# SAMA7D65D4GN8 register map
Vendor: Microchip Technology; Series: SAMA7D6; File version: 0
Registers are 32-bit, read-write, reset 0x0 unless marked. A register's access mark holds for its fields unless they carry their own. Offsets are from the block's base; [hi:lo] are bit positions; {n}, {i} and the like mark numbered series; 'fields as' and 'values as' point back to an identical list.

## DDRPUBL — DDR SDRAM PHY Utility Block Lite
Base 0xE3804000; register names take the prefix DDR3PHY_
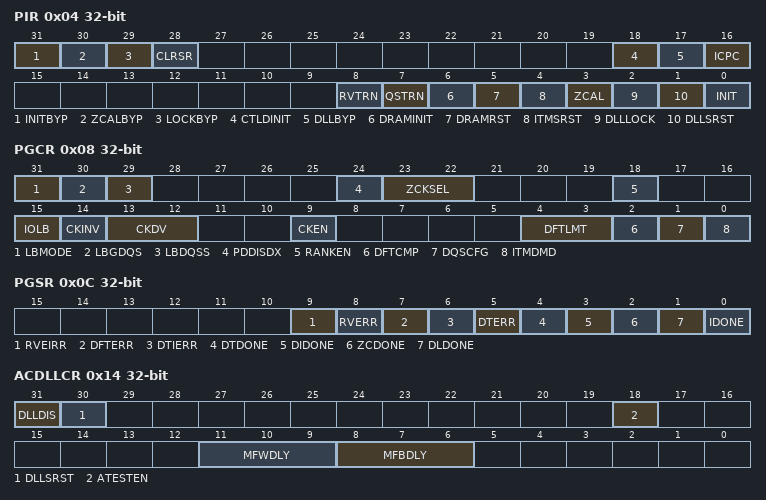
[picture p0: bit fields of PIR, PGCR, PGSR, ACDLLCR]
0x04 PIR — PHY Initialization Register
  [31] INITBYP — Initialization Bypass: Bypasses or stops, if set, all initialization routines currently running, including PHY initialization, DRAM initialization, and PHY training.
  [30] ZCALBYP — Impedance Calibration Bypass: Bypasses or stops, if set, impedance calibration of all ZQ control blocks that automatically triggers after reset. Impedance calibration may be triggered manually using INIT and ZCAL bits of the PIR register. This bit is self-clearing.
  [29] LOCKBYP — DLL Lock Bypass: Bypasses or stops, if set, the waiting of DLLs to lock. DLL lock wait is automatically triggers after reset. DLL lock wait may be triggered manually using INIT and DLLLOCK bits of the PIR register. This bit is self-clearing.
  [28] CLRSR — Clear Status Registers
  [18] CTLDINIT — Controller DRAM Initialization: Indicates if set that DRAM initialization will be performed by the controller. Otherwise if not set it indicates that DRAM initialization will be performed using the built-in initialization sequence or using software through the configuration port.
  [17] DLLBYP — DLL Bypass: A setting of 1 on this bit will put all PHY DLLs in bypass mode. A bypassed DLL is also powered down (disabled).
  [16] ICPC — Initialization Complete Pin Configuration: Specifies how the DFI 2.1 initialization complete output pin should be used to indicate the status of initialization.
  [8] RVTRN — Read DQS gate training (QSTRN) and RV training (RVTRN) should normally be run together. It is expected RVTRN is normally be set whenever PIR.QSTRN is set.
  [7] QSTRN — Read DQS Training: Executes a PUBL training routine to determine the optimum position of the read data DQS strobe for maximum system timing margins.
  [6] DRAMINIT — DRAM Initialization: Executes the DRAM initialization sequence.
  [5] DRAMRST — DRAM Reset (DDR3 Only): Issues a reset to the DRAM (by driving the DRAM reset pin low) and wait 200us. This can be triggered in isolation or with the full DRAM initialization (DRAMINIT). For the latter case, the reset is issued and 200us is waited before starting the full initialization sequence.
  [4] ITMSRST — Interface Timing Module Soft Reset: Soft resets the interface timing modules for the data and data strobes, i.e., it asserts the ITM soft reset (srstb) signal.
  [3] ZCAL — Impedance Calibrate: Performs PHY impedance calibration.
  [2] DLLLOCK — DLL Lock: Waits for the PHY DLLs to lock.
  [1] DLLSRST — DLL Soft Rest: Soft resets all PHY DLLs by driving the DLL soft reset pin.
  [0] INIT — Initialization Trigger: A write of '1' to this bit triggers the DDR system initialization, including PHY initialization, DRAM initialization, and PHY training. The exact initialization steps to be executes are specified in bits 1 to 6 of this register. A bit setting of 1 means the step will be executed as part of the initialization sequence, while a setting of '0' means the step will be bypassed. The initialization trigger bit is self-clearing.
0x08 PGCR — PHY General Configuration Register
  [31] LBMODE — Loopback Mode: Indicates if set that the PHY/PUB is in loopback mode
  [30] LBGDQS — Loopback DQS Gating: Selects the DQS gating mode that should be used when the PHY is in loopback mode, including BIST loopback mode.
  [29] LBDQSS — Loopback DQS Shift: Selects how the read DQS is shifted during loopback to ensure that the read DQS is centered into the read data eye.
  [24] PDDISDX — Power Down Disabled Byte: Indicates if set that the DLL and I/Os of a disabled byte should be powered down.
  [23:22] ZCKSEL — Impedance Clock Divider Select: Impedance Clock Divider Select: Selects the divide ratio for the clock used by the impedance control logic. The source clock for the divider is the configuration port clock signal (cfg_clk or pclk), depending on which configuration port type used (see 'Impedance Calibration' ).
  [18] RANKEN — Rank Enable: Specifies the ranks that are enabled for data-training. Bit 0 controls rank 0, bit 1 controls rank 1, bit 2 controls rank 2, and bit 3 controls rank 3. Setting the bit to '1' enables the rank, and setting it to '0' disables the rank.
  [15] IOLB — I/O Loop-Back Select: Selects where inside the I/O the loop-back of signals happens. Not applicable to D3A I/Os.
  [14] CKINV — CK Invert: Specifies if set that CK/CK# should be inverted. Otherwise CK/CK# toggles with normal polarity.
  [13:12] CKDV — CK Disable Value: Specifies the static value that should be driven on CK/CK# pair(s) when the pair(s) is disabled. CKDV[0] specifies the value for CK and CKDV[1] specifies the value for CK#.
  [9] CKEN — CK Enable: Controls whether the CK going to the SDRAM is enabled (toggling) or disabled (static value defined by CKDV). One bit for each of the three CK pairs.
  [4:3] DFTLMT — DQS Drift Limit: Specifies the expected limit of drift on read data strobes. A drift of this value or greater is reported as a drift error through the host port error flag.
  [2] DFTCMP — DQS Drift Compensation: Enables or disables DQS drift compensation.
  [1] DQSCFG — DQS Gating Configuration: Selects one of the two DQS gating schemes.
  [0] ITMDMD — ITM DDR Mode: Selects whether ITMS uses DQS and DQS# or it only uses DQS.
0x0C PGSR ro — PHY General Status Register
  [9] RVEIRR — Read Valid Training Intermittent Error: If set, indicates that there was an intermittent error during read valid training, such as a pass was followed by a fail then followed by another pass.
  [8] RVERR — Read Valid Training Error: If set, indicates that a valid read valid placement could not be found during read valid training.
  [7] DFTERR — DQS Drift Error: If set, indicates that at least one of the read data strobes has drifted by more than or equal to the drift limit set in the PHY General Configuration Register (PGCR).
  [6] DTIERR — DQS Gate Training Intermittent Error: If set, indicates that there was an intermittent error during DQS gate training, such as a pass was followed by a fail then followed by another pass.
  [5] DTERR — DQS GateTraining Error: If set, indicates that a valid DQS gating window could not be found during DQS gate training.
  [4] DTDONE — Data Training Done: Indicates, if set, that the PHY has finished doing data training.
  [3] DIDONE — DRAM Initialization Done: Indicates if set that DRAM initialization has completed.
  [2] ZCDONE — Impedance Calibration Done: Indicates if set that impedance calibration has completed.
  [1] DLDONE — DLL Lock Done: Indicates if set that DLL locking has completed.
  [0] IDONE — Initialization Done: Indicates if set that the DDR system initialization has completed. This bit is set after all the selected initialization routines in PIR register have completed.
0x10 DLLGCR — DLL General Control Register
  [23] BPS200 — Bypass Mode Frequency Range
0x14 ACDLLCR — AC DLL Control Register
  [31] DLLDIS — DLL Disable: A disabled DLL is bypassed. Default ('0') is DLL enabled.
  [30] DLLSRST — DLL Soft Rest: Soft resets the AC DLL by driving the DLL soft reset pin.
  [18] ATESTEN — Analog Test Enable: Enables the analog test signal to be output on the DLL analog test output (test_out_a). The DLL analog test output is tri-stated when this bit is '0'.
  [11:9] MFWDLY — Master Feed-Forward Delay Trim: Used to trim the delay in the master DLL feedforward path.
  [8:6] MFBDLY — Master Feed-Back Delay Trim: Used to trim the delay in the master DLL feedback path.
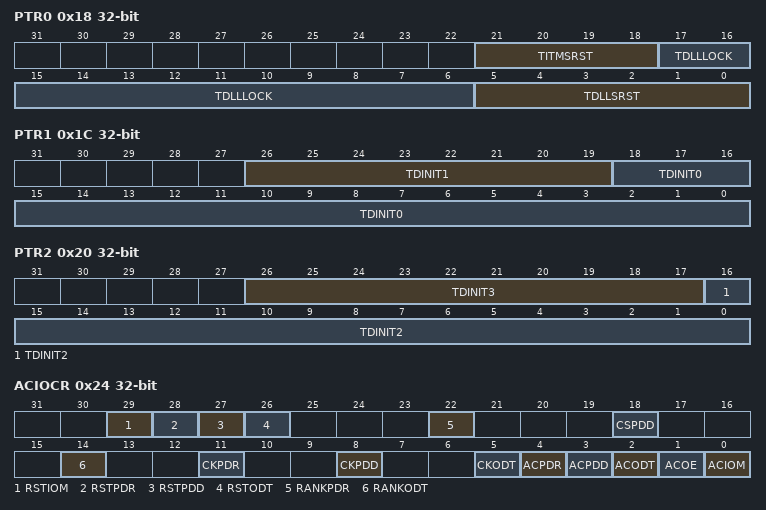
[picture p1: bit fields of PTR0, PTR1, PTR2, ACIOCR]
0x18 PTR0 — PHY Timing Register 0
  [21:18] TITMSRST — ITM Soft Reset Time: Number of configuration clock cycles that the ITM soft reset pin must remain asserted when the soft reset is applied to the ITMs. This must correspond to a value that is equal to or more than 8 controller clock cycles. Default value corresponds to 8 controller clock cycles.
  [17:6] TDLLLOCK — DLL Lock Time: Number of configuration clock cycles for the DLL to stabilize and lock, i.e. number of clock cycles from when the DLL reset pin is de-asserted to when the DLL has locked and is ready for use. Refer to the PHY databook for the DLL lock time. Default value corresponds to 5.12us at 533MHz.
  [5:0] TDLLSRST — DLL Soft Reset Time: Number of configuration clock cycles that the DLL soft reset pin must remain asserted when the soft reset is triggered through the PHY
0x1C PTR1 — PHY Timing Register 1
  [26:19] TDINIT1 — DRAM Initialization Time 1.
  [18:0] TDINIT0 — DRAM Initialization Time 0.
0x20 PTR2 — PHY Timing Register 2
  [26:17] TDINIT3 — DRAM Initialization Time 3.
  [16:0] TDINIT2 — DRAM Initialization Time 2.
0x24 ACIOCR — AC I/O Configuration Register
  [29] RSTIOM — SDRAM Reset I/O Mode: Selects SSTL mode (when set to 0) or CMOS mode (when set to 1) of the I/O for SDRAM Reset.
  [28] RSTPDR — SDRAM Reset Power Down Receiver: Powers down, when set, the input receiver on the I/O for SDRAM RST# pin.
  [27] RSTPDD — SDRAM Reset Power Down Driver: Powers down, when set, the output driver on the I/O for SDRAM RST# pin.
  [26] RSTODT — SDRAM Reset On-Die Termination: Enables, when set, the on-die termination on the I/O for SDRAM RST# pin.
  [22] RANKPDR — Rank Power Down Receiver: Powers down, when set, the input receiver on the I/O
  [18] CSPDD — CS# Power Down Driver: Powers down, when set, the output driver on the I/O for CS#[3:0] pins. PDD[0] controls the power down for CS#[0], PDD[1] controls the power down for CS#[1], and so on. CKE and ODT driver power down is controlled by DSGCR register.
  [14] RANKODT — Rank On-Die Termination: Enables, when set, the on-die termination on the I/O for CKE[3:0], ODT[3:0], and CS#[3:0] pins. RANKODT[0] controls the on-die termination for CKE[0], ODT[0], and CS#[0], RANKODT[1] controls the on-die termination for CKE[1], ODT[1], and CS#[1], and so on.
  [11] CKPDR — CK Power Down Receiver: Powers down, when set, the input receiver on the I/O for CK[0], CK[1], and CK[2] pins, respectively.
  [8] CKPDD — CK Power Down Driver: Powers down, when set, the output driver on the I/O for CK[0], CK[1], and CK[2] pins, respectively.
  [5] CKODT — CK On-Die Termination: Enables, when set, the on-die termination on the I/O for CK[0], CK[1], and CK[2] pins, respectively.
  [4] ACPDR — AC Power Down Receiver: Powers down, when set, the input receiver on the I/O for RAS#, CAS#, WE#, BA[2:0], and A[15:0] pins, as well as the optional DIMM PAR_IN pin and LPDDR TPD pin.
  [3] ACPDD — AC Power Down Driver: Powers down, when set, the output driver on the I/O for RAS#, CAS#, WE#, BA[2:0], and A[15:0] pins, as well as the optional DIMM PAR_IN pin.
  [2] ACODT — Address/Command On-Die Termination: Enables, when set, the on-die termination on the I/O for RAS#, CAS#, WE#, BA[2:0], and A[15:0] pins, as well as the optional DIMM PAR_IN pin and LPDDR TPD pin.
  [1] ACOE — Address/Command Output Enable: Enables, when set, the output driver on the I/O for all address and command pins, as well as the optional DIMM PAR_IN pin and LPDDR TPD pin.
  [0] ACIOM — Address/Command I/O Mode: Selects SSTL mode (when set to 0) or CMOS mode (when set to 1) of the I/O for all address and command pins, as well as the optional DIMM PAR_IN pin and LPDDR TPD pin.
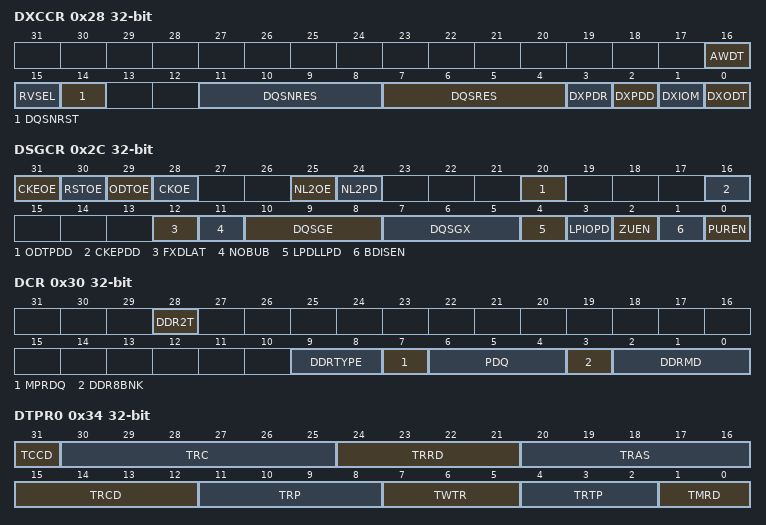
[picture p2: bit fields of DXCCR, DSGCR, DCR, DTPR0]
0x28 DXCCR — DATX8 I/O Configuration Register
  [16] AWDT — Active Window Data Train: Indicates if set that data training (DQS gate training and read valid training) should be performed with active DQS gate window. This is just for debug purposes. The default is to perform training with passive windowing.
  [15] RVSEL — ITMD Read Valid Select: Selects the scheme used for ITMD read valid.
  [14] DQSNRST — DQS# Reset: Indicates, if set, that the ITMS of DQS# should always be put in reset such that its output enable is always '1' and its data output is always '0'. This is done by driving the oe_set_b and do_rst_b pins of this ITMS to '0' in order to force the unused DQS# PAD to a known state of '0' in applications that don't use DQS# such as in LPDDR mode.
  [11:8] DQSNRES — DQS# Resistor: Selects the on-die pull-up/pull-down resistor for DQS# pins. Same encoding as DQSRES.
  [7:4] DQSRES — DQS Resistor: Selects the on-die pull-down/pull-up resistor for DQS pins.
  [3] DXPDR — Data Power Down Receiver: Powers down, when set, the input receiver on I/O for
  [2] DXPDD — Data Power Down Driver: Powers down, when set, the output driver on I/O for DQ, DM, and DQS/DQS# pins of all DATX8 macros. This bit is ORed with the PDD configuration bit of the individual DATX8
  [1] DXIOM — Data I/O Mode: Selects SSTL mode (when set to 0) or CMOS mode (when set to 1) of the I/O for DQ, DM, and DQS/DQS# pins of all DATX8 macros. This bit is ORed with the IOM configuration bit of the individual DATX8
  [0] DXODT — Data On-Die Termination: Enables, when set, the on-die termination on the I/O for DQ, DM, and DQS/DQS# pins of all DATX8 macros. This bit is ORed with the ODT configuration bit of the individual DATX8
0x2C DSGCR — DFI Configuration Register
  [31] CKEOE — SDRAM CKE Output Enable: Enables, when set, the output driver on the I/O for SDRAM CKE pins.
  [30] RSTOE — SDRAM Reset Output Enable: Enables, when set, the output driver on the I/O for SDRAM RST# pin.
  [29] ODTOE — SDRAM ODT Output Enable: Enables, when set, the output driver on the I/O for SDRAM ODT pins.
  [28] CKOE — SDRAM CK Output Enable: Enables, when set, the output driver on the I/O for SDRAM CK/CK# pins.
  [25] NL2OE — Non-LPDDR2/LPDDR3 Output Enable: Enables, when set, the output driver on the I/O for non-LPDDR2/LPDDR3 (ODT, RAS#, CAS#, WE#, and BA) pins. This may be used when a chip that is designed for both LPDDR2/LPDDR3 and other DDR modes is being used in LPDDR2/LPDDR3 mode. For these pins, the I/O output enable signal (OE) is an AND of this bit and the respective output enable bit in ACIOCR or DSGCR registers.
  [24] NL2PD — Non-LPDDR2/LPDDR3 Power Down: Powers down, when set, the output driver and the input receiver on the I/O for non-LPDDR2/LPDDR3 (ODT, RAS#, CAS#, WE#,
  [20] ODTPDD — ODT Power Down Driver: Powers down, when set, the output driver on the I/O for ODT[3:0] pins. ODTPDD[0] controls the power down for ODT[0], ODTPDD[1] controls the power down for ODT[1], and so on.
  [16] CKEPDD — CKE Power Down Driver: Powers down, when set, the output driver on the I/O for CKE[3:0] pins. CKEPDD[0] controls the power down for CKE[0], CKEPDD[1] controls the power down for CKE[1], and so on.
  [12] FXDLAT — Fixed Latency: Specified whether all reads should be returned to the controller with a fixed read latency. Enabling fixed read latency increases the read latency.
  [11] NOBUB — No Bubbles: Specified whether reads should be returned to the controller with no bubbles. Enabling no-bubble reads increases the read latency.
  [10:8] DQSGE — DQS Gate Early: Specifies the number of clock cycles for which the DQS gating must be enabled earlier than its normal position. Only applicable when using PDQSR I/O cell, passive DQS gating and no drift compensation. This field is recommended to be set to zero for all DDR types other than
  [7:5] DQSGX — DQS Gate Extension: Specifies the number of clock cycles for which the DQS gating must be extended beyond the normal burst length width. Only applicable when using PDQSR I/O cell, passive DQS gating and no drift compensation. This field is recommended to be set to zero for all DDR types other than
  [4] LPDLLPD — Low Power DLL Power Down: Specifies if set that the PHY should respond to the DFI low power opportunity request and power down the DLL of the PHY if the wakeup time request satisfies the DLL lock time.
  [3] LPIOPD — Low Power I/O Power Down: Specifies if set that the PHY should respond to the DFI low power opportunity request and power down the I/Os of the PHY.
  [2] ZUEN — Impedance Update Enable: Specifies if set that the PHY should perform impedance calibration (update) whenever there is a controller initiated DFI update request.
  [1] BDISEN — Byte Disable Enable: Specifies if set that the PHY should respond to DFI byte disable request. Otherwise the byte disable from the DFI is ignored in which case bytes can only be disabled using the DXnGCR register.
  [0] PUREN — PHY Update Request Enable: Specifies if set, that the PHY should issue PHYinitiated DFI update request when there is DQS drift of more than 3/4 of a clock cycle within one continuous (back-to-back) read burst. By default the PHY issues PHYinitiated update requests and the controller should respond otherwise the PHY may return erroneous values. The option to disable it is provided only for silicon evaluation and testing.
0x30 DCR — DRAM Configuration Register
  [28] DDR2T — DDR 2T Timing: Indicates if set that 2T timing should be used by PUB internally generated SDRAM transactions.
  [9:8] DDRTYPE — DDR Type: Selects the DDR type for the specified LPDDR mode.
  [7] MPRDQ — Multi-Purpose Register (MPR) DQ (DDR3 Only): Specifies the value that is driven on non-primary DQ pins during MPR reads.
  [6:4] PDQ — Primary DQ (DDR3 Only): Specifies the DQ pin in a byte that is designated as a primary pin for Multi-Purpose Register (MPR) reads. Valid values are 0 to 7 for DQ[0] to DQ[7], respectively.
  [3] DDR8BNK — DDR 8-Bank: Indicates if set that the SDRAM used has 8 banks. tRPA = tRP+1 and tFAW are used for 8-bank DRAMs, other tRPA = tRP and no tFAW is used. Note that
  [2:0] DDRMD — DDR Mode: SDRAM DDR mode.
0x34 DTPR0 — SDRAM Timing Parameters Register 0
  [31] TCCD — Read to read and write to write command delay.
  [30:25] TRC — Activate to activate command delay (same bank). Valid values are 2 to 42.
  [24:21] TRRD — Activate to activate command delay (different banks). Valid values are 1 to 8.
  [20:16] TRAS — Activate to precharge command delay. Valid values are 2 to 31.
  [15:12] TRCD — Activate to read or write delay. Minimum time from when an activate command is issued to when a read or write to the activated row can be issued. Valid values are 2 to 11.
  [11:8] TRP — Precharge command period: The minimum time between a precharge command and any other command. Note that the Controller automatically derives tRPA for 8bank DDR2 devices by adding 1 to tRP. Valid values are 2 to 11.
  [7:5] TWTR — Internal write to read command delay. Valid values are 1 to 6.
  [4:2] TRTP — Internal read to precharge command delay. Valid values are 2 to 6. Note that even though RTP does not apply to JEDEC DDR devices, this parameter must still be set to a minimum value of 2 for DDR because the Controller always uses the DDR2 equation, AL + BL/2 + max(RTP,2) - 2, to compute the read to precharge timing (which is BL/2 for JEDEC DDR).
  [1:0] TMRD — Load mode cycle time: The minimum time between a load mode register command and any other command. For DDR3 this is the minimum time between two load mode register commands. Valid values for DDR2 are 2 to 3. For DDR3, the value used for tMRD is 4 plus the value programmed in these bits, i.e. tMRD value for DDR3 ranges from 4 to 7. For LPDDR3, the value used for tMRD is 8 plus the value programmed in these bits.
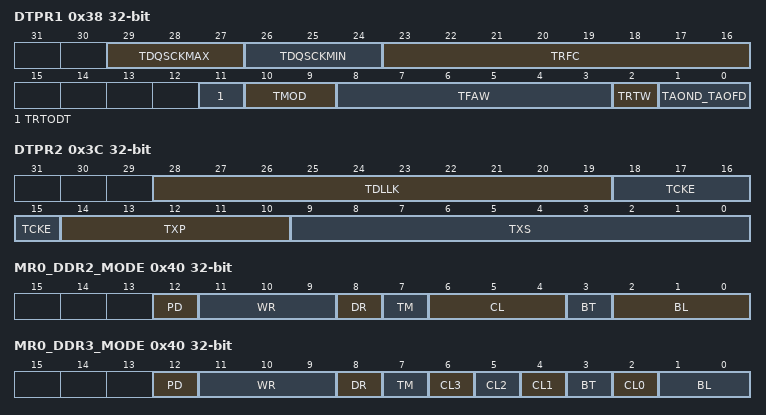
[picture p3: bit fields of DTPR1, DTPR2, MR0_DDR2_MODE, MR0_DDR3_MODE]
0x38 DTPR1 — SDRAM Timing Parameters Register 1
  [29:27] TDQSCKMAX — Maximum DQS output access time from CK/CK# (LPDDR2 only). This value is used for implementing read-to-write spacing. Valid values are 1 to 7.
  [26:24] TDQSCKMIN — DQS output access time from CK/CK# (LPDDR2/3 only). This value is used for computing the read latency. Valid values are 0 to 7. This value is derived from the corresponding parameter in the SDRAM datasheet divided by the clock cycle time without rounding up. The fractional remainder is automatically adjusted for by data training in quarter clock cycle units. If data training is not performed then this fractional remainder must be converted to quarter clock cycle units and the gating registers (DXnDQSTR) adjusted accordingly.
  [23:16] TRFC — Refresh-to-Refresh: Indicates the minimum time, in clock cycles, between two refresh commands or between a refresh and an active command. This is derived from the minimum refresh interval from the datasheet, tRFC(min), divided by the clock cycle time. The default number of clock cycles is for the largest JEDEC tRFC(min parameter value supported.
  [11] TRTODT — Read to ODT delay (DDR3 only). Specifies whether ODT can be enabled immediately after the read post-amble or one clock delay has to be added.
  [10:9] TMOD — Load mode update delay (DDR3 only). The minimum time between a load mode register command and a non-load mode register command.
  [8:3] TFAW — 4-bank activate period. No more than 4-bank activate commands may be issued in a given tFAW period. Only applies to 8-bank devices. Valid values are 2 to 31.
  [2] TRTW — Read to Write command delay.
  [1:0] TAOND_TAOFD — ODT Turn-On/Turn-Off Delays (DDR2 only)
0x3C DTPR2 — SDRAM Timing Parameters Register 2
  [28:19] TDLLK — DLL locking time. Valid values are 2 to 1023.
  [18:15] TCKE — CKE minimum pulse width. Also specifies the minimum time that the SDRAM must remain in power down or self refresh mode. For DDR3 this parameter must be set to the value of tCKESR which is usually bigger than the value of tCKE. Valid values are 2 to 15.
  [14:10] TXP — Power down exit delay. The minimum time between a power down exit command and any other command. This parameter must be set to the maximum of the various minimum power down exit delay parameters specified in the SDRAM datasheet, i.e. max(tXP, tXARD, tXARDS) for DDR2 and max(tXP, tXPDLL) for DDR3. Valid values are 2 to 31.
  [9:0] TXS — Self refresh exit delay. The minimum time between a self refresh exit command and any other command. This parameter must be set to the maximum of the various minimum self refresh exit delay parameters specified in the SDRAM datasheet, i.e. max(tXSNR, tXSRD) for DDR2 and max(tXS, tXSDLL) for DDR3. Valid values are 2 to 1023.
0x40 MR0_DDR2_MODE — Mode Register
  [12] PD — Power-Down Control
  [11:9] WR — Write Recovery
  [8] DR — DLL Reset
  [7] TM — Operating Mode
  [6:4] CL — CAS Latency
  [3] BT — Burst Type
  [2:0] BL — Burst Length
0x40 MR0_DDR3_MODE (alternate view of MR0_DDR2_MODE) — Mode Register
  [12] PD — Power-Down Control
  [11:9] WR — Write Recovery
  [8] DR — DLL Reset
  [7] TM — Operating Mode
  [6] CL3 — CAS Latency
  [5] CL2 — CAS Latency
  [4] CL1 — CAS Latency
  [3] BT — Burst Type
  [2] CL0 — CAS Latency
  [1:0] BL — Burst Length
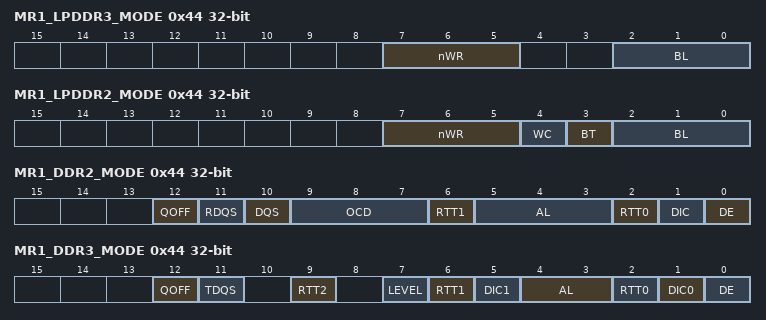
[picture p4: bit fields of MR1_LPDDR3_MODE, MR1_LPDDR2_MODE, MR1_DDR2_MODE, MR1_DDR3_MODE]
0x44 MR1_LPDDR3_MODE — Extended Mode Register 1
  [7:5] nWR — Write Recovery
  [2:0] BL — Burst Length
0x44 MR1_LPDDR2_MODE (alternate view of MR1_LPDDR3_MODE) — Extended Mode Register 1
  [7:5] nWR — Write Recovery
  [4] WC — Wrap Control
  [3] BT — Burst Type
  [2:0] BL — Burst Length
0x44 MR1_DDR2_MODE (alternate view of MR1_LPDDR3_MODE) — Extended Mode Register 1
  [12] QOFF — Output Enable/Disable
  [11] RDQS — RDQS Enable/Disable
  [10] DQS — DDR_DQSN Enable/Disable
  [9:7] OCD — Off-Chip Driver (OCD) Impedance Calibration
  [6] RTT1 — On-Die Termination
  [5:3] AL — Posted CAS Additive Latency
  [2] RTT0 — On-Die Termination
  [1] DIC — Output Driver Impedance Control
  [0] DE — DLL Enable/Disable
0x44 MR1_DDR3_MODE (alternate view of MR1_LPDDR3_MODE) — Extended Mode Register 1
  [12] QOFF — Output Enable/Disable
  [11] TDQS — Termination Data Strobe
  [9] RTT2 — On-Die Termination
  [7] LEVEL — Write Leveling Enable
  [6] RTT1 — On-Die Termination
  [5] DIC1 — Output Driver Impedance Control
  [4:3] AL — Posted CAS Additive Latency
  [2] RTT0 — On-Die Termination
  [1] DIC0 — Output Driver Impedance Control
  [0] DE — DLL Enable/Disable
0x48 MR2_LPDDR3_MODE — Extended Mode Register 2
  [3:0] RL_WL — Read and Write Latency
0x48 MR2_LPDDR2_MODE (alternate view of MR2_LPDDR3_MODE) — Extended Mode Register 2
  [3:0] RL_WL — Read and Write Latency
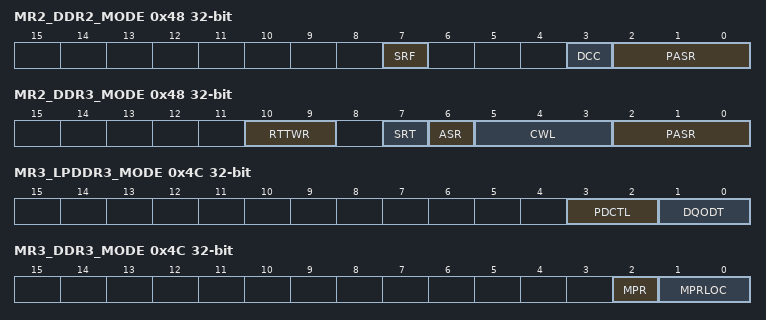
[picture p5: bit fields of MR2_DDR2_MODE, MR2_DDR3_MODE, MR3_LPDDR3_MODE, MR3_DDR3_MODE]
0x48 MR2_DDR2_MODE (alternate view of MR2_LPDDR3_MODE) — Extended Mode Register 2
  [7] SRF — Self-Refresh Rate
  [3] DCC — Duty Cycle Corrector
  [2:0] PASR — Partial Array Self Refresh
0x48 MR2_DDR3_MODE (alternate view of MR2_LPDDR3_MODE) — Extended Mode Register 2
  [10:9] RTTWR — Dynamic ODT
  [7] SRT — Self-Refresh Temperature Range
  [6] ASR — Auto Self-Refresh
  [5:3] CWL — CAS Write Latency
  [2:0] PASR — Partial Array Self Refresh
0x4C MR3_LPDDR3_MODE — Extended Mode Register 3
  [3:2] PDCTL — Power-Down Control
  [1:0] DQODT — On-Die Termination
0x4C MR3_LPDDR2_MODE (alternate view of MR3_LPDDR3_MODE) — Extended Mode Register 3
  [3:0] DS — Drive Strength
0x4C MR3_DDR2_MODE (alternate view of MR3_LPDDR3_MODE) — Extended Mode Register 3
0x4C MR3_DDR3_MODE (alternate view of MR3_LPDDR3_MODE) — Extended Mode Register 3
  [2] MPR — Multi-Purpose Register Enable
  [1:0] MPRLOC — Multi-Purpose Register (MPR) Location
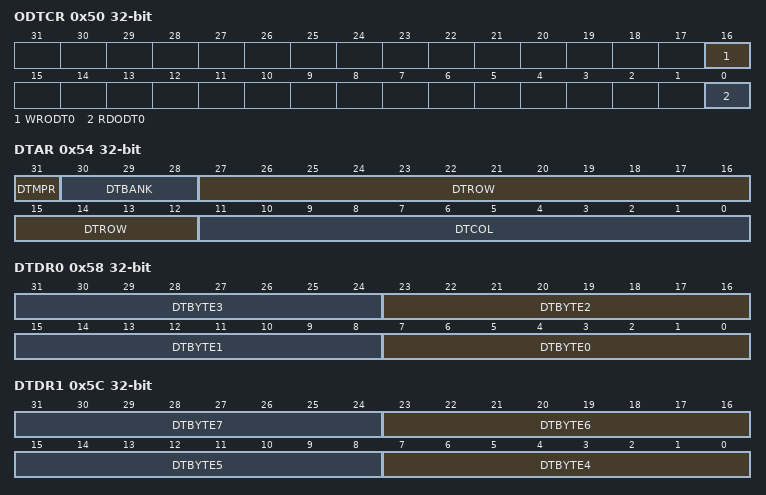
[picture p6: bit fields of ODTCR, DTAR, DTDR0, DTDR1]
0x50 ODTCR — ODT Configuration Register
  [16] WRODT0 — Write ODT: Specifies whether ODT should be enabled ('1') or disabled ('0') on each of the up to four ranks when a write command is sent to rank n. WRODT0,
  [0] RDODT0
0x54 DTAR — Data Training Address Register
  [31] DTMPR — Data Training Using MPR (DDR3 Only): Specifies, if set, that data-training should use the SDRAM Multi-Purpose Register (MPR) register. Otherwise data-training is performed by first writing to some locations in the SDRAM and then reading them back.
  [30:28] DTBANK — Data Training Bank Address: Selects the SDRAM bank address to be used during data training.
  [27:12] DTROW — Data Training Row Address: Selects the SDRAM row address to be used during data training.
  [11:0] DTCOL — Data Training Column Address: Selects the SDRAM column address to be used during data training. The lower four bits of this address must always be '0000'.
0x58 DTDR0 — Data Training Data Register 0
  [8n+7:8n] DTBYTE{n} (n=0..3) — Data Training Data: The first 4 bytes of data used during data training. This same data byte is used for each Byte Lane. Default sequence is a walking 1 while toggling data every data cycle.
0x5C DTDR1 — Data Training Data Register 1
  [8n-25:8n-32] DTBYTE{n} (n=4..7) — Data Training Data: The second 4 bytes of data used during data training. This same data byte is used for each Byte Lane. Default sequence is a walking 1 while toggling data every data cycle.
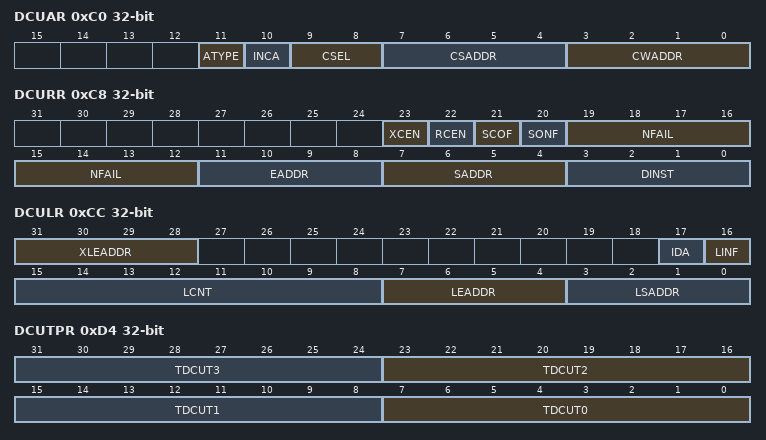
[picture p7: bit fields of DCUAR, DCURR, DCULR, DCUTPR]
0xC0 DCUAR — DCU Address Register
  [11] ATYPE — Access Type: Specifies the type of access to be performed using this address. Valid values are: 0 = Write access
  [10] INCA — Increment Address: Specifies, if set, that the cache address specified in WADDR and SADDR should be automatically incremented after each access of the cache. The increment happens in such a way that all the slices of a selected word are first accessed before going to the next word.
  [9:8] CSEL — Cache Select: Selects the cache to be accessed.
  [7:4] CSADDR — Cache Slice Address: Address of the cache slice to be accessed.
  [3:0] CWADDR — Cache Word Address: Address of the cache word to be accessed.
0xC4 DCUDR — DCU Data Register
  [31:0] CDATA — Cache Data: Data to be written to or read from a cache. This data corresponds to the cache word slice specified by the DCU Address Register.
0xC8 DCURR — DCU Run Register
  [23] XCEN — Expected Compare Enable: Indicates if set that read data coming back from the SDRAM should be should be compared with the expected data.
  [22] RCEN — Read Capture Enable: Indicates if set that read data coming back from the SDRAM should be captured into the read data cache.
  [21] SCOF — Stop Capture On Full: Specifies if set that the capture of read data should stop when the capture cache is full.
  [20] SONF — Stop On Nth Fail: Specifies if set that the execution of commands and the capture of read data should stop when there are N read data failures. The number of failures is specified by NFAIL. Otherwise commands execute until the end of the program or until manually stopped using a STOP command.
  [19:12] NFAIL — Number of Failures: Specifies the number of failures after which the execution of commands and the capture of read data should stop if SONF bit of this register is set. Execution of commands and the capture of read data will stop after (NFAIL+1) failures if SONF is set.
  [11:8] EADDR — End Address: Cache word address where the execution of command should end.
  [7:4] SADDR — Start Address: Cache word address where the execution of commands should begin.
  [3:0] DINST — DCU Instruction: Selects the DCU command to be executed.
0xCC DCULR — DCU Loop Register
  [31:28] XLEADDR — Expected Data Loop End Address: The last expected data cache word address that contains valid expected data. Expected data should looped between 0 and this address.
  [17] IDA — Increment DRAM Address: Indicates if set that DRAM addresses should be incremented every time a DRAM read/write command inside the loop is executed.
  [16] LINF — Loop Infinite: Indicates if set that the loop should be executed indefinitely until stopped by the STOP command. Otherwise the loop is execute LCNT times.
  [15:8] LCNT — Loop Count: The number of times that the loop should be executed if LINF is not set.
  [7:4] LEADDR — Loop End Address: Command cache word address where the loop should end.
  [3:0] LSADDR — Loop Start Address: Command cache word address where the loop should start.
0xD0 DCUGCR — DCU General Configuration Register
  [15:0] RCSW — Read Capture Start Word: The capture and compare of read data should start after Nth word. For example setting this value to 12 will skip the first 12 read data.
0xD4 DCUTPR — DCU Timing Parameter Register
  [8n+7:8n] TDCUT{n} (n=0..3) — DCU Generic Timing Parameter {n}.
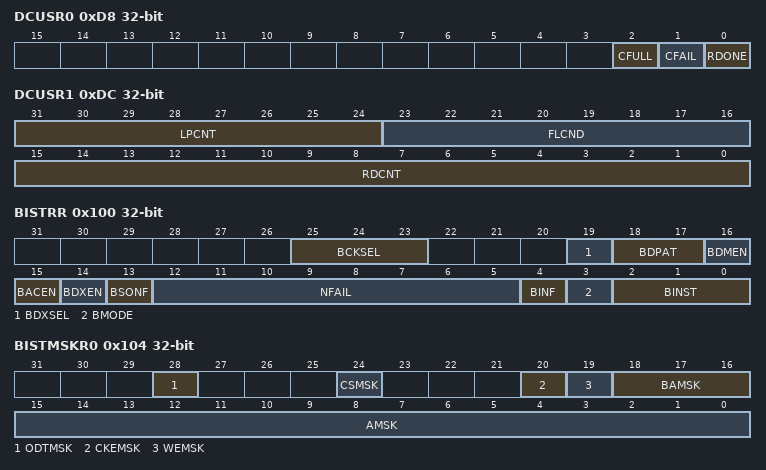
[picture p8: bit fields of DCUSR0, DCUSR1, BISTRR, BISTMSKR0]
0xD8 DCUSR0 — DCU Status-0 Register
  [2] CFULL — Capture Full: Indicates if set that the capture cache is full.
  [1] CFAIL — Capture Fail: Indicates if set that at least one read data word has failed.
  [0] RDONE — Run Done: Indicates if set that the DCU has finished executing the commands in the command cache. This bit is also set to indicate that a STOP command has successfully been executed and command execution has stopped.
0xDC DCUSR1 — DCU Status-1 Register
  [31:24] LPCNT — Loop Count: Indicates the value of the loop count. This is useful when the program has stooped because of failures to assess how many reads were executed before first fail.
  [23:16] FLCND — Fail Count: Number of read words that have failed.
  [15:0] RDCNT — Read Count: Number of read words returned from the SDRAM.
0x100 BISTRR — BIST Run Register
  [25:23] BCKSEL — BIST DDR_CLK Select
  [19] BDXSEL — BIST Data Byte Lane Select
  [18:17] BDPAT — BIST Data Pattern
  [16] BDMEN — BIST Data Mask Enable
  [15] BACEN — BIST AC Enable
  [14] BDXEN — BIST Data Enable
  [13] BSONF — BIST Stop On Nth Fail
  [12:5] NFAIL — Number of Failures
  [4] BINF — BIST Infinite Run
  [3] BMODE — BIST Mode
  [2:0] BINST — BIST Instruction
0x104 BISTMSKR0 — BIST Mask 0 Register
  [28] ODTMSK — ODT Mask Bit
  [24] CSMSK — DDR_CSN Mask Bit
  [20] CKEMSK — DDR_CKE Mask Bit
  [19] WEMSK — DDR_WEN Mask Bit
  [18:16] BAMSK — DDR_BA Mask Bit
  [15:0] AMSK — DDR_A Mask Bit
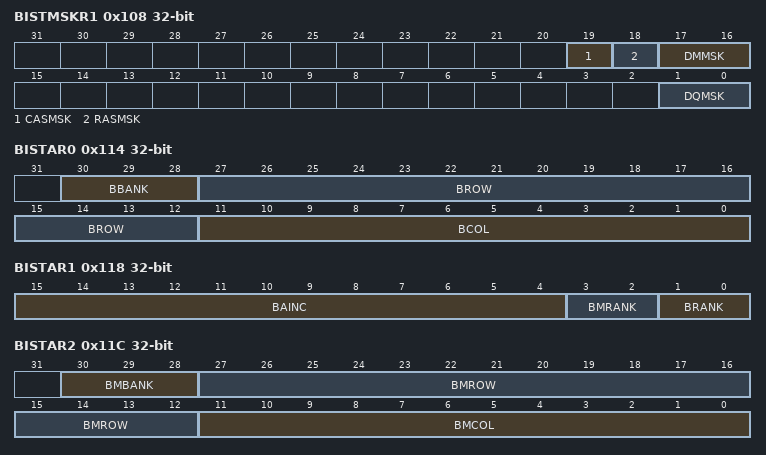
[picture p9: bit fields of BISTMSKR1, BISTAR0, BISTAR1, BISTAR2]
0x108 BISTMSKR1 — BIST Mask 1 Register
  [19] CASMSK — DDR_CASN Mask Bit
  [18] RASMSK — DDR_RASN Mask Bit
  [17:16] DMMSK — DDR_DQM Mask Bit
  [1:0] DQMSK — DDR_D Mask Bit
0x10C BISTWCR — BIST Word Count Register
  [15:0] BWCNT — BIST Word Count
0x110 BISTLSR — BIST LFSR Seed Register
  [31:0] SEED — LFSR seed for pseudo-random BIST patterns.
0x114 BISTAR0 — BIST Address 0 Register
  [30:28] BBANK — BIST Bank Address
  [27:12] BROW — BIST Row Address
  [11:0] BCOL — BIST Column Address
0x118 BISTAR1 — BIST Address 1 Register
  [15:4] BAINC — BIST Address Increment
  [3:2] BMRANK — BIST Maximum Rank
  [1:0] BRANK — BIST Rank
0x11C BISTAR2 — BIST Address 2 Register
  [30:28] BMBANK — BIST Maximum Bank Address
  [27:12] BMROW — BIST Maximum Row Address
  [11:0] BMCOL — BIST Maximum Column Address
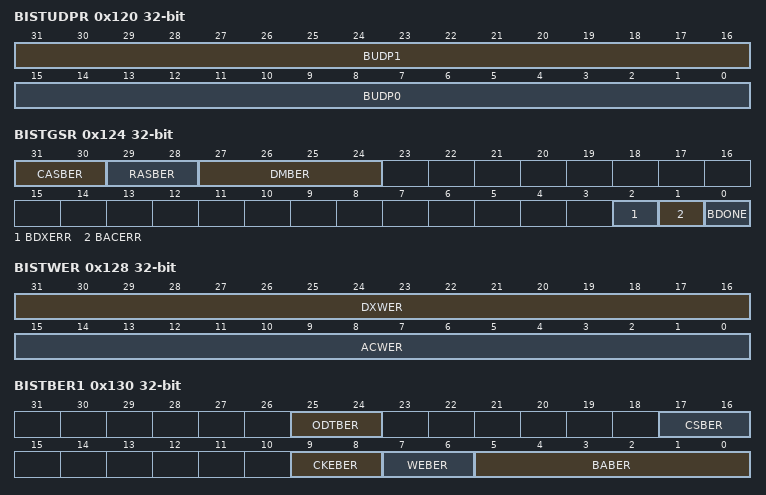
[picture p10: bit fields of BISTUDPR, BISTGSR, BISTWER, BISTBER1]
0x120 BISTUDPR — BIST User Data Pattern Register
  [31:16] BUDP1 — BIST User Data Pattern 1
  [15:0] BUDP0 — BIST User Data Pattern 0
0x124 BISTGSR — BIST General Status Register
  [31:30] CASBER — DDR_CASN Bit Error
  [29:28] RASBER — DDR_RASN Bit Error
  [27:24] DMBER — DDR_DQM Bit Error
  [2] BDXERR — BIST Data Error
  [1] BACERR — BIST Address/Command Error
  [0] BDONE — BIST Done
0x128 BISTWER — BIST Word Error Register
  [31:16] DXWER — Byte Word Error
  [15:0] ACWER — Address/Command Word Error
0x12C BISTBER0 — BIST Bit Error 0 Register
  [31:0] ABER — Address Bit Error
0x130 BISTBER1 — BIST Bit Error 1 Register
  [25:24] ODTBER — DDR_ODT Bit Error
  [17:16] CSBER — DDR_CSN Bit Error
  [9:8] CKEBER — DDR_CKE Bit Error
  [7:6] WEBER — DDR_WEN Bit Error
  [5:0] BABER — Bank Address Bit Error
0x134 BISTBER2 — BIST Bit Error 2 Register
  [31:0] DQBER — Data Bit Error
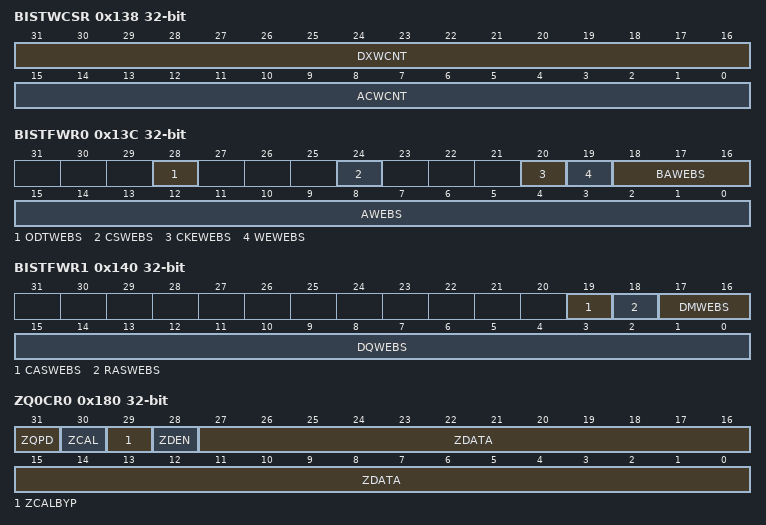
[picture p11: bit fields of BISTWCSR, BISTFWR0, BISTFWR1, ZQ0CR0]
0x138 BISTWCSR — BIST Word Count Status Register
  [31:16] DXWCNT — Byte Word Count
  [15:0] ACWCNT — Address/Command Word Count
0x13C BISTFWR0 — BIST Fail Word 0 Register
  [28] ODTWEBS — DDR_ODT Word Error Bit Status
  [24] CSWEBS — DDR_CSN Word Error Bit Status
  [20] CKEWEBS — DDR_CKE Word Error Bit Status
  [19] WEWEBS — DDR_WEN Word Error Bit Status
  [18:16] BAWEBS — DDR_BA Word Error Bit Status
  [15:0] AWEBS — DDR_A Word Error Bit Status
0x140 BISTFWR1 — BIST Fail Word 1 Register
  [19] CASWEBS — DDR_CASN Word Error Bit Status
  [18] RASWEBS — DDR_RASN Word Error Bit Status
  [17:16] DMWEBS — DDR_DQM Word Error Bit Status
  [15:0] DQWEBS — DDR_D Word Error Bit Status
0x180 ZQ0CR0 — ZQ Impedence Control Register 0
  [31] ZQPD — ZQ Power Down
  [30] ZCAL — Impedance Calibration Trigger
  [29] ZCALBYP — Impedance Calibration Bypass
  [28] ZDEN — Impedance Override Enable
  [27:0] ZDATA — Impedance Override Data
0x184 ZQ0CR1 — ZQ Impedence Control Register 1
  [7:0] ZPROG — Impedance Divide Ratio
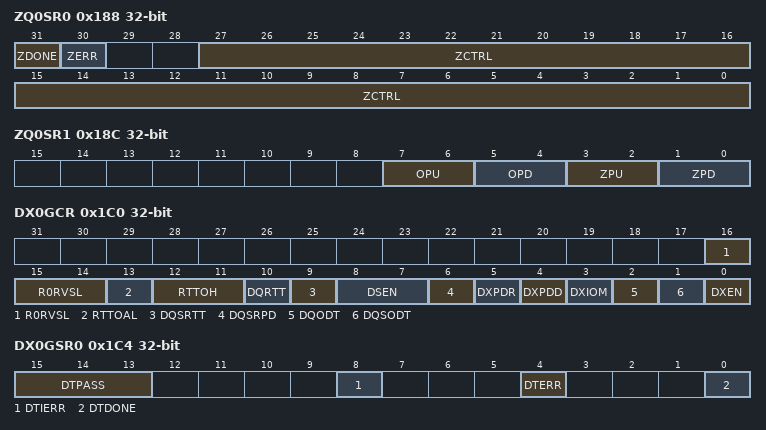
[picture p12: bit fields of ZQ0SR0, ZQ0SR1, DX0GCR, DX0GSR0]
0x188 ZQ0SR0 — ZQ Impedence Control Status Register 0
  [31] ZDONE — Impedance Calibration Done
  [30] ZERR — Impedance Calibration Error
  [27:0] ZCTRL — Impedance Control
0x18C ZQ0SR1 — ZQ Impedence Control Status Register 1
  [7:6] OPU — On-Die Termination (ODT) Pull-Up Calibration Status
  [5:4] OPD — On-Die Termination (ODT) Pull-Down Calibration Status
  [3:2] ZPU — Output Impedance Pull-Up Calibration Status
  [1:0] ZPD — Output Impedance Pull-Down Calibration Status
0x1C0 DX0GCR — DATX8 General Configuration Register
  [16:14] R0RVSL — Rank 0 ITMD Read Valid System Latency
  [13] RTTOAL — RTT On Additive Latency
  [12:11] RTTOH — RTT Output Hold
  [10] DQRTT — DDR_D Dynamic RTT Control
  [9] DQSRTT — DDR_DQS Dynamic RTT Control
  [8:7] DSEN — Write DDR_DQS Enable
  [6] DQSRPD — DQSR Power Down
  [5] DXPDR — Data Power Down Receiver
  [4] DXPDD — Data Power Down Driver
  [3] DXIOM — Data I/O Mode
  [2] DQODT — Data On-Die Termination
  [1] DQSODT — DDR_DQS On-Die Termination
  [0] DXEN — Data Byte Enable
0x1C4 DX0GSR0 — DATX8 General Status Register 0
  [15:13] DTPASS — DDR_DQS GateTraining Pass Count
  [8] DTIERR — DDR_DQS Gate Training Intermittent Error
  [4] DTERR — DDR_DQS Gate Training Error
  [0] DTDONE — Data Training Done
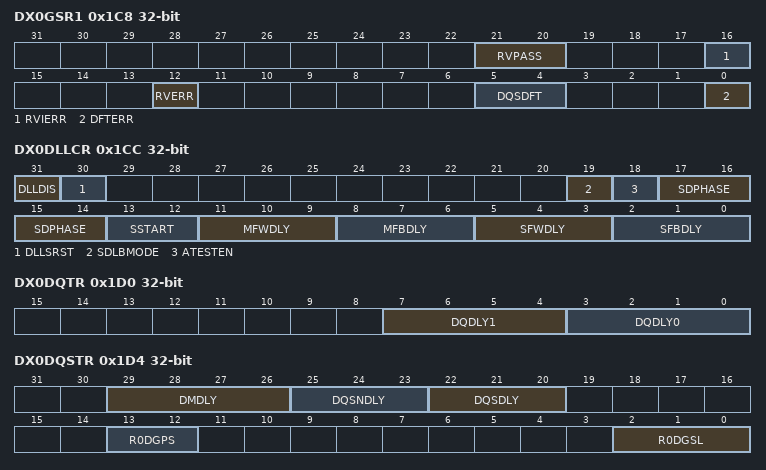
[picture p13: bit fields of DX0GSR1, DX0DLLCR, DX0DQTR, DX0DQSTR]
0x1C8 DX0GSR1 — DATX8 General Status Register 1
  [21:20] RVPASS — Read Valid Training Pass Count
  [16] RVIERR — Read Valid Training Intermittent Error
  [12] RVERR — Read Valid Training Error
  [5:4] DQSDFT — DQS Drift
  [0] DFTERR — DQS Drift Error
0x1CC DX0DLLCR — DATX8 DLL Control Register
  [31] DLLDIS — DLL Disable
  [30] DLLSRST — DLL Soft Reset
  [19] SDLBMODE — Client DLL Loopback Mode
  [18] ATESTEN — Analog Test Enable
  [17:14] SDPHASE — Client DLL Phase Trim
  [13:12] SSTART — Client Auto Start-Up
  [11:9] MFWDLY — Host Feed-Forward Delay Trim
  [8:6] MFBDLY — Host Feedback Delay Trim
  [5:3] SFWDLY — Client Feed-Forward Delay Trim
  [2:0] SFBDLY — Client Feedback Delay Trim
0x1D0 DX0DQTR — DATX8 DQ Timing Register
  [7:4] DQDLY1 — DDR_D Delay
  [3:0] DQDLY0 — DDR_D Delay
0x1D4 DX0DQSTR — DATX8 DQS Timing Register
  [29:26] DMDLY — DDR_DQM Delay
  [25:23] DQSNDLY — DDR_DQSN Delay
  [22:20] DQSDLY — DQS Delay
  [13:12] R0DGPS — Rank 0 DQS Gating Phase Select
  [2:0] R0DGSL — Rank 0 DQS Gating System Latency
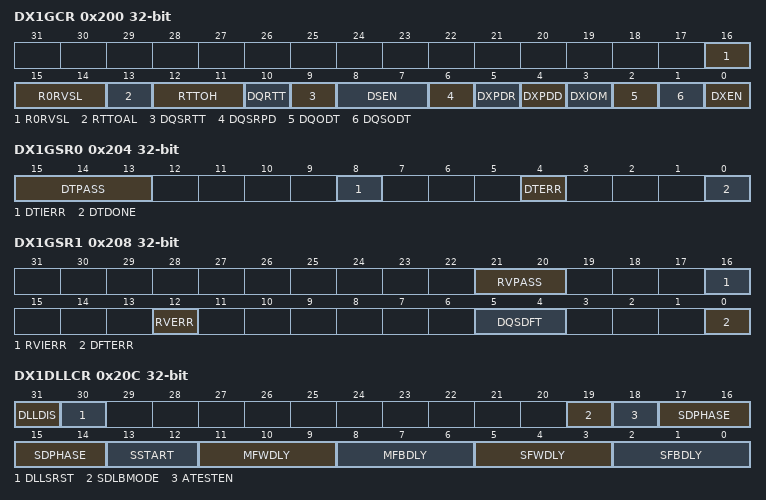
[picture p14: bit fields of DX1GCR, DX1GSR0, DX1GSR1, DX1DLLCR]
0x200 DX1GCR — DATX8 General Configuration Register
  fields as DX0GCR
0x204 DX1GSR0 — DATX8 General Status Register 0
  fields as DX0GSR0
0x208 DX1GSR1 — DATX8 General Status Register 1
  fields as DX0GSR1
0x20C DX1DLLCR — DATX8 DLL Control Register
  fields as DX0DLLCR
0x210 DX1DQTR — DATX8 DQ Timing Register
  [7:4] DQDLY1 — DDR_D Delay
  [3:0] DQDLY0 — DDR_D Delay
0x214 DX1DQSTR — DATX8 DQS Timing Register
  fields as DX0DQSTR
